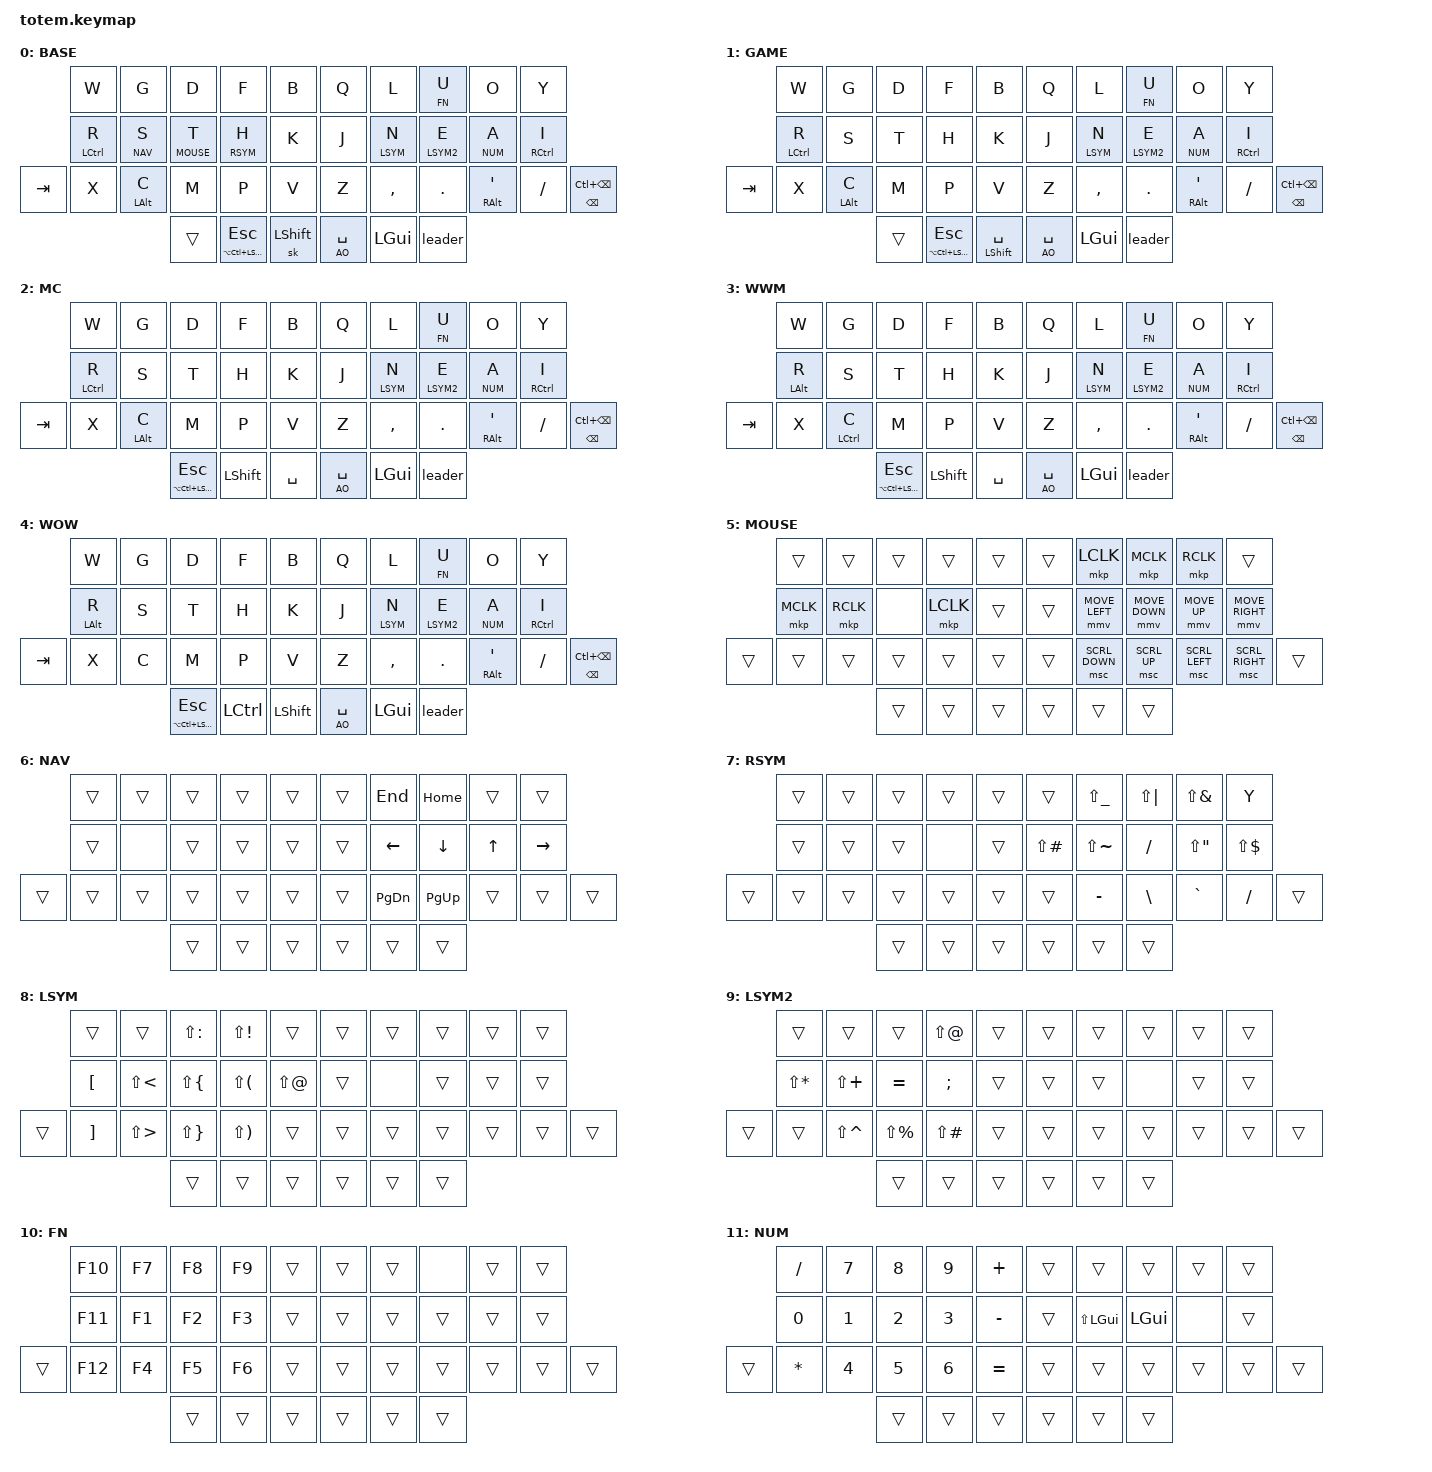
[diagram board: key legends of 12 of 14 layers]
//
//                                                        ▀▀▀▀▀     ▀▀▀▀▀          ▀▀█▀▀
//                                                        ▄▀▀▀▄  ▄  ▄▀▀▀▄  ▄  ▄▀▀▀▄  █  ▄▀▀▀▄
//                                                        █   █  █  █   █  █  █   █  █  █   █
//                                                         ▀▀▀   █   ▀▀▀   █   ▀▀▀   ▀   ▀▀▀
//                                                               █      ▄▄▄█▄▄▄    █   █  
//                                                               ▀      █  █  █     █▄█
//                                                             ▀▀▀▀▀    █  █  █      ▀
//                                                                      ▀  ▀  ▀
//
// ▄▄▄▄▄▄▄▄▄▄▄▄▄▄▄▄▄▄▄▄▄▄▄▄▄▄▄▄▄▄▄▄▄▄▄▄▄▄▄▄▄▄▄▄▄▄▄▄▄▄▄▄▄▄▄▄▄▄▄▄▄▄▄▄▄▄▄▄▄▄▄▄▄▄▄▄▄▄▄▄▄▄▄▄▄▄▄▄▄▄▄▄▄▄▄▄▄▄▄▄▄▄▄▄▄▄▄▄▄▄▄▄▄▄▄▄▄▄▄▄▄▄▄▄▄▄▄▄▄▄▄▄▄▄▄▄▄▄▄▄▄▄▄▄▄▄▄▄▄
#define ZMK_POINTING_DEFAULT_MOVE_VAL 1100  // default: 600
#define ZMK_POINTING_DEFAULT_SCRL_VAL 20    // default: 10

#include <behaviors.dtsi>
#include <dt-bindings/zmk/bt.h>
#include <dt-bindings/zmk/keys.h>
#include <dt-bindings/zmk/pointing.h>

#define BASE 0
#define GAME 1
#define MC 2
#define WWM 3
#define WOW 4
#define MOUSE 5
#define NAV 6
#define RSYM 7
#define LSYM 8
#define LSYM2 9
#define FN 10
#define NUM 11
#define AO 12
#define BT 13

/ {
    combos {
        compatible = "zmk,combos";

        Enter {
            bindings = <&kp ENTER>;
            key-positions = <14 13>;
        };

        Backspace {
            bindings = <&kp BACKSPACE>;
            key-positions = <2 12>;
        };

        Tab {
            bindings = <&kp TAB>;
            key-positions = <15 16>;
        };
    };

    behaviors {
        mtl: mtl {
            compatible = "zmk,behavior-hold-tap";
            label = "Mod tap left";
            bindings = <&kp>, <&kp>;

            #binding-cells = <2>;
            tapping-term-ms = <280>;
            quick-tap-ms = <175>;
            require-prior-idle-ms = <150>;
            flavor = "balanced";
            hold-trigger-on-release;
            hold-trigger-key-positions = <32 33 34 35 36 37 26 15 5 27 6 7 8 9 16 17 18 19 28 29 30 31>;
        };

        mtr: mtr {
            compatible = "zmk,behavior-hold-tap";
            label = "Mod tap right";
            bindings = <&kp>, <&kp>;

            #binding-cells = <2>;
            tapping-term-ms = <280>;
            quick-tap-ms = <175>;
            require-prior-idle-ms = <150>;
            flavor = "balanced";
            hold-trigger-on-release;
            hold-trigger-key-positions = <32 33 34 35 36 37 0 1 2 3 4 10 11 12 13 14 20 21 22 23 24 25 32 33>;
        };

        ltl: ltl {
            compatible = "zmk,behavior-hold-tap";
            label = "Layer tap left";
            bindings = <&mo>, <&kp>;

            #binding-cells = <2>;
            tapping-term-ms = <280>;
            quick-tap-ms = <175>;
            require-prior-idle-ms = <150>;
            flavor = "balanced";
            hold-trigger-on-release;
            hold-trigger-key-positions = <32 33 34 35 36 37 26 15 5 27 6 7 8 9 16 17 18 19 28 29 30 31>;
        };

        ltr: ltr {
            compatible = "zmk,behavior-hold-tap";
            label = "Layer tap right";
            bindings = <&mo>, <&kp>;

            #binding-cells = <2>;
            tapping-term-ms = <280>;
            quick-tap-ms = <175>;
            require-prior-idle-ms = <150>;
            flavor = "balanced";
            hold-trigger-on-release;
            hold-trigger-key-positions = <32 33 34 35 36 37 0 1 2 3 4 10 11 12 13 14 20 21 22 23 24 25 32 33>;
        };

        leader: leader {
            compatible = "zmk,behavior-leader-key";
            #binding-cells = <0>;
            reset { sequence = <L L>; bindings = <&to BASE>; };
            game { sequence = <L G>; bindings = <&tog GAME>; };
            mc { sequence = <L M>; bindings = <&tog MC>; };
            wwm { sequence = <L W>; bindings = <&tog WWM>; };
            wow { sequence = <L D>; bindings = <&tog WOW>; };
        };
    };

    keymap {
        compatible = "zmk,keymap";

        // ▄▄▄▄▄▄▄▄▄▄▄▄▄▄▄▄▄▄▄▄▄▄▄▄▄▄▄▄▄▄▄▄▄▄▄▄▄▄▄▄▄▄▄▄▄▄▄▄▄▄▄▄▄▄▄▄▄▄▄▄▄▄▄▄▄▄▄▄▄▄▄▄▄▄▄▄▄▄▄▄▄▄▄▄▄▄▄▄▄▄▄▄▄▄▄▄▄▄▄▄▄▄▄▄▄▄▄▄▄▄▄▄▄▄▄▄▄▄▄▄▄▄▄▄▄▄▄▄▄▄▄▄▄▄▄▄▄▄▄▄▄▄▄▄▄▄▄▄▄

        base {
            // ┏━━━━━━━━━━━━━━━━━━━━━━━━━━━━━━━━━━━━━━━┓

            label = "BASE";

            // ┗━━━━━━━━━━━━━━━━━━━━━━━━━━━━━━━━━━━━━━━┛
            //             ┏━━━━━━━━━━━┳━━━━━━━━━━━┳━━━━━━━━━━━┳━━━━━━━━━━━┳━━━━━━━━━━━┓   ┏━━━━━━━━━━━┳━━━━━━━━━━━┳━━━━━━━━━━━┳━━━━━━━━━━━┳━━━━━━━━━━━┓
            //             ┃     Q     ┃     W     ┃     F     ┃     P     ┃     G     ┃   ┃     J     ┃     L     ┃     U     ┃     Y     ┃     ;     ┃
            //             ┣━━━━━━━━━━━╋━━━━━━━━━━━╋━━━━━━━━━━━╋━━━━━━━━━━━╋━━━━━━━━━━━┫   ┣━━━━━━━━━━━╋━━━━━━━━━━━╋━━━━━━━━━━━╋━━━━━━━━━━━╋━━━━━━━━━━━┫
            //             ┃     A     ┃     R     ┃     S     ┃     T     ┃     D     ┃   ┃     H     ┃     N     ┃     E     ┃     I     ┃     O     ┃
            // ┏━━━━━━━━━━━╋━━━━━━━━━━━╋━━━━━━━━━━━╋━━━━━━━━━━━╋━━━━━━━━━━━╋━━━━━━━━━━━┫   ┣━━━━━━━━━━━╋━━━━━━━━━━━╋━━━━━━━━━━━╋━━━━━━━━━━━╋━━━━━━━━━━━╋━━━━━━━━━━━┓
            // ┃     Q     ┃     Z     ┃     X     ┃     C     ┃     V     ┃     B     ┃   ┃     K     ┃     M     ┃     ,     ┃     .     ┃     /     ┃     \     ┃
            // ┗━━━━━━━━━━━┻━━━━━━━━━━━┻━━━━━━━━━━━╋━━━━━━━━━━━╋━━━━━━━━━━━╋━━━━━━━━━━━┫   ┣━━━━━━━━━━━╋━━━━━━━━━━━╋━━━━━━━━━━━╋━━━━━━━━━━━┻━━━━━━━━━━━┻━━━━━━━━━━━┛
            //                                     ┃    DEL    ┃    TAB    ┃    SPC    ┃   ┃   ENTER   ┃           ┃   BSPC    ┃
            //                                     ┗━━━━━━━━━━━┻━━━━━━━━━━━┻━━━━━━━━━━━┛   ┗━━━━━━━━━━━┻━━━━━━━━━━━┻━━━━━━━━━━━┛

            bindings = <
         &kp W         &kp G            &kp D            &kp F                       &kp B             &kp Q        &kp L         &ltr FN U     &kp O                        &kp Y
         &mtl LCTRL R  &ltl NAV S       &ltl MOUSE T     &ltl RSYM H                 &kp K             &kp J        &ltr LSYM N   &ltr LSYM2 E  &ltr NUM A                   &mtr RCTRL I
&kp TAB  &kp X         &mtl LEFT_ALT C  &kp M            &kp P                       &kp V             &kp Z        &kp COMMA     &kp DOT       &mtr RIGHT_ALT SINGLE_QUOTE  &kp FSLH      &mt BACKSPACE LC(BACKSPACE)
                                        &trans           &mt LA(LC(LEFT_SHIFT)) ESC  &sk LEFT_SHIFT    &lt AO SPACE &kp LEFT_GUI  &leader
            >;
        };

        Game {
            label = "GAME";

            bindings = <
         &kp W         &kp G            &kp D     &kp F                       &kp B                   &kp Q        &kp L         &ltr FN U     &kp O                        &kp Y
         &mtl LCTRL R  &kp S            &kp T     &kp H                       &kp K                   &kp J        &ltr LSYM N   &ltr LSYM2 E  &ltr NUM A                     &mtr RCTRL I
&kp TAB  &kp X         &mtl LEFT_ALT C  &kp M     &kp P                       &kp V                   &kp Z        &kp COMMA     &kp DOT       &mtr RIGHT_ALT SINGLE_QUOTE  &kp FSLH      &mt BACKSPACE LC(BACKSPACE)
                                        &trans    &mt LA(LC(LEFT_SHIFT)) ESC  &mt LEFT_SHIFT SPACE    &lt AO SPACE &kp LEFT_GUI  &leader
            >;
        };

        Mc {
            label = "MC";

            bindings = <
         &kp W         &kp G            &kp D     &kp F                       &kp B                   &kp Q        &kp L         &ltr FN U     &kp O                        &kp Y
         &mtl LCTRL R  &kp S            &kp T     &kp H                       &kp K                   &kp J        &ltr LSYM N   &ltr LSYM2 E  &ltr NUM A                     &mtr RCTRL I
&kp TAB  &kp X         &mtl LEFT_ALT C  &kp M     &kp P                       &kp V                   &kp Z        &kp COMMA     &kp DOT       &mtr RIGHT_ALT SINGLE_QUOTE  &kp FSLH      &mt BACKSPACE LC(BACKSPACE)
                                        &mt LA(LC(LEFT_SHIFT)) ESC   &kp LEFT_SHIFT  &kp SPACE        &lt AO SPACE &kp LEFT_GUI  &leader
            >;
        };

        Wwm {
            label = "WWM";

            bindings = <
         &kp W         &kp G            &kp D     &kp F                       &kp B                   &kp Q        &kp L         &ltr FN U     &kp O                        &kp Y
         &mtl LEFT_ALT R  &kp S         &kp T     &kp H                       &kp K                   &kp J        &ltr LSYM N   &ltr LSYM2 E  &ltr NUM A                     &mtr RCTRL I
&kp TAB  &kp X         &mtl LCTRL C     &kp M     &kp P                       &kp V                   &kp Z        &kp COMMA     &kp DOT       &mtr RIGHT_ALT SINGLE_QUOTE  &kp FSLH      &mt BACKSPACE LC(BACKSPACE)
                                        &mt LA(LC(LEFT_SHIFT)) ESC   &kp LEFT_SHIFT  &kp SPACE        &lt AO SPACE &kp LEFT_GUI  &leader
            >;
        };

        Wow {
            label = "WOW";

            bindings = <
         &kp W         &kp G            &kp D     &kp F                       &kp B                   &kp Q        &kp L         &ltr FN U     &kp O                        &kp Y
         &mtl LEFT_ALT R  &kp S         &kp T     &kp H                       &kp K                   &kp J        &ltr LSYM N   &ltr LSYM2 E  &ltr NUM A                     &mtr RCTRL I
&kp TAB  &kp X         &kp C            &kp M     &kp P                       &kp V                   &kp Z        &kp COMMA     &kp DOT       &mtr RIGHT_ALT SINGLE_QUOTE  &kp FSLH      &mt BACKSPACE LC(BACKSPACE)
                                        &mt LA(LC(LEFT_SHIFT)) ESC &kp LCTRL  &kp LEFT_SHIFT        &lt AO SPACE &kp LEFT_GUI  &leader
            >;
        };

        Mouse {
            bindings = <
        &trans     &trans     &trans  &trans     &trans    &trans  &mkp LCLK       &mkp MCLK       &mkp RCLK       &trans
        &mkp MCLK  &mkp RCLK  &none   &mkp LCLK  &trans    &trans  &mmv MOVE_LEFT  &mmv MOVE_DOWN  &mmv MOVE_UP    &mmv MOVE_RIGHT
&trans  &trans     &trans     &trans  &trans     &trans    &trans  &msc SCRL_DOWN  &msc SCRL_UP    &msc SCRL_LEFT  &msc SCRL_RIGHT  &trans
                              &trans  &trans     &trans    &trans  &trans          &trans
            >;

            label = "MOUSE";
        };

        Nav {
            bindings = <
        &trans  &trans  &trans  &trans  &trans    &trans  &kp END        &kp HOME     &trans  &trans
        &trans  &none   &trans  &trans  &trans    &trans  &kp LEFT       &kp DOWN     &kp UP  &kp RIGHT
&trans  &trans  &trans  &trans  &trans  &trans    &trans  &kp PAGE_DOWN  &kp PAGE_UP  &trans  &trans     &trans
                        &trans  &trans  &trans    &trans  &trans         &trans
            >;

            label = "NAV";
        };

        Rsym {
            bindings = <
        &trans  &trans  &trans  &trans  &trans    &trans         &kp LS(UNDER)  &kp LS(PIPE)  &kp LS(AMPS)  &kp Y
        &trans  &trans  &trans  &none   &trans    &kp LS(POUND)  &kp LS(TILDE)  &kp FSLH      &kp LS(DQT)   &kp LS(DLLR)
&trans  &trans  &trans  &trans  &trans  &trans    &trans         &kp MINUS      &kp BSLH      &kp GRAVE     &kp FSLH      &trans
                        &trans  &trans  &trans    &trans         &trans         &trans
            >;

            label = "RSYM";
        };

        Lsym {
            bindings = <
        &trans    &trans      &kp LS(COLON)  &kp LS(EXCL)  &trans        &trans  &trans  &trans  &trans  &trans
        &kp LBKT  &kp LS(LT)  &kp LS(LBRC)   &kp LS(LPAR)  &kp LS(AT)    &trans  &none   &trans  &trans  &trans
&trans  &kp RBKT  &kp LS(GT)  &kp LS(RBRC)   &kp LS(RPAR)  &trans        &trans  &trans  &trans  &trans  &trans  &trans
                              &trans         &trans        &trans        &trans  &trans  &trans
            >;

            label = "LSYM";
        };

        Lsym2 {
            bindings = <
        &trans        &trans         &trans         &kp LS(AT)     &trans    &trans  &trans  &trans  &trans  &trans
        &kp LS(STAR)  &kp LS(PLUS)   &kp EQUAL      &kp SEMI       &trans    &trans  &trans  &none   &trans  &trans
&trans  &trans        &kp LS(CARET)  &kp LS(PRCNT)  &kp LS(POUND)  &trans    &trans  &trans  &trans  &trans  &trans  &trans
                                     &trans         &trans         &trans    &trans  &trans  &trans
            >;

            label = "LSYM2";
        };

        Fn {
            bindings = <
        &kp F10  &kp F7  &kp F8  &kp F9  &trans    &trans  &trans  &none   &trans  &trans
        &kp F11  &kp F1  &kp F2  &kp F3  &trans    &trans  &trans  &trans  &trans  &trans
&trans  &kp F12  &kp F4  &kp F5  &kp F6  &trans    &trans  &trans  &trans  &trans  &trans  &trans
                         &trans  &trans  &trans    &trans  &trans  &trans
            >;

            label = "FN";
        };

        Num {
            bindings = <
        &kp FSLH  &kp N7  &kp N8  &kp N9  &kp PLUS     &trans  &trans            &trans        &trans  &trans
        &kp N0    &kp N1  &kp N2  &kp N3  &kp MINUS    &trans  &kp LS(LEFT_GUI)  &kp LEFT_GUI  &none   &trans
&trans  &kp STAR  &kp N4  &kp N5  &kp N6  &kp EQUAL    &trans  &trans            &trans        &trans  &trans  &trans
                          &trans  &trans  &trans       &trans  &trans            &trans
            >;

            label = "NUM";
        };

        AO {
            bindings = <
        &trans  &trans  &trans  &trans     &trans     &trans      &trans  &trans  &trans  &kp DELETE
        &trans  &trans  &trans  &kp ENTER  &trans     &tog MOUSE  &trans  &trans  &trans  &trans
&trans  &trans  &trans  &trans  &trans     &trans     &to BASE    &trans  &trans  &trans  &sys_reset  &mo BT
                        &trans  &trans     &kp TAB    &none       &trans  &trans
            >;

            label = "AO";
        };

        Bluetooth {
            bindings = <
            &trans  &trans        &trans        &trans        &bt BT_CLR_ALL    &trans  &trans  &trans  &trans  &trans
            &trans  &bt BT_SEL 0  &bt BT_SEL 1  &bt BT_SEL 2  &trans            &trans  &trans  &trans  &trans  &trans
&bt BT_CLR  &trans  &bt BT_SEL 3  &bt BT_SEL 4  &trans        &trans            &trans  &trans  &trans  &trans  &trans  &trans
                                  &trans        &trans        &trans            &trans  &trans  &trans
            >;

            label = "BT";
        };
    };
};
